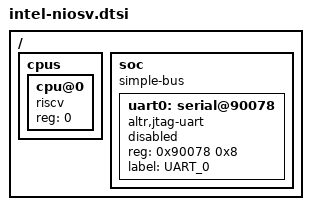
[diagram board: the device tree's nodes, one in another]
/*
 * SPDX-License-Identifier: Apache-2.0
 */

/dts-v1/;

#include <skeleton.dtsi>

/ {
	#address-cells = <1>;
	#size-cells = <1>;

	cpus {
		#address-cells = <1>;
		#size-cells = <0>;
		cpu@0 {
			device_type = "cpu";
			compatible = "riscv";
			reg = <0>;
		};

	};

	soc {
		#address-cells = <1>;
		#size-cells = <1>;
		compatible = "simple-bus";
		ranges;
    
        uart0: serial@90078 {
			compatible = "altr,jtag-uart";
            reg = <0x90078 0x8>;
			status = "disabled";
			label = "UART_0";
		};

	};
};
